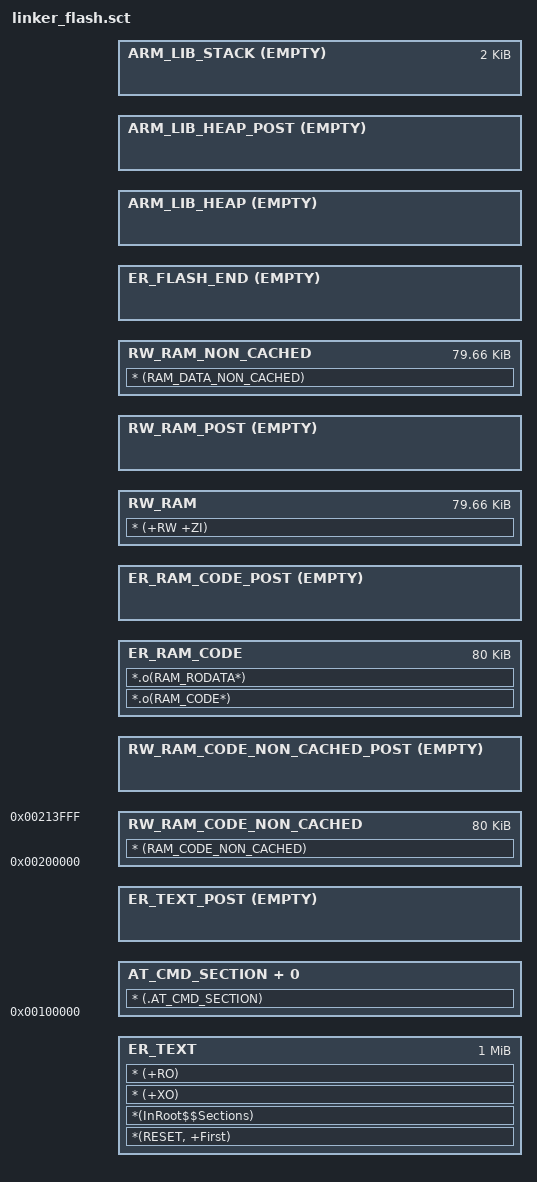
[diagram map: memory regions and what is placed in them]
#! armclang -E --target=arm-arm-none-eabi -mcpu=cortex-m4 -xc
; command above MUST be in first line (no comment above!)

/* ----------------------------------------------------------------------------
 * Copyright (c) 2020-2030 chipsea Limited. All rights reserved.
 *
 * Redistribution and use in source and binary forms, with or without modification,
 * are permitted provided that the following conditions are met:
 *   1. Redistributions of source code must retain the above copyright notice,
 *      this list of conditions and the following disclaimer.
 *   2. Redistributions in binary form must reproduce the above copyright notice,
 *      this list of conditions and the following disclaimer in the documentation
 *      and/or other materials provided with the distribution.
 *   3. Neither the name of chipseaelectronics nor the names of its contributors
 *      may be used to endorse or promote products derived from this software
 *      without specific prior written permission.
 *
 * THIS SOFTWARE IS PROVIDED BY THE COPYRIGHT HOLDERS AND CONTRIBUTORS "AS IS"
 * AND ANY EXPRESS OR IMPLIED WARRANTIES, INCLUDING, BUT NOT LIMITED TO, THE
 * IMPLIED WARRANTIES OF MERCHANTABILITY AND FITNESS FOR A PARTICULAR PURPOSE ARE
 * DISCLAIMED. IN NO EVENT SHALL THE COPYRIGHT HOLDER OR CONTRIBUTORS BE LIABLE
 * FOR ANY DIRECT, INDIRECT, INCIDENTAL, SPECIAL, EXEMPLARY, OR CONSEQUENTIAL
 * DAMAGES (INCLUDING, BUT NOT LIMITED TO, PROCUREMENT OF SUBSTITUTE GOODS OR
 * SERVICES; LOSS OF USE, DATA, OR PROFITS; OR BUSINESS INTERRUPTION) HOWEVER
 * CAUSED AND ON ANY THEORY OF LIABILITY, WHETHER IN CONTRACT, STRICT LIABILITY,
 * OR TORT (INCLUDING NEGLIGENCE OR OTHERWISE) ARISING IN ANY WAY OUT OF THE USE
 * OF THIS SOFTWARE, EVEN IF ADVISED OF THE POSSIBILITY OF SUCH DAMAGE.
 *
 * -------------------------------------------------------------------------- */

/**
 * @file     cst92f41_flash.sct
 * @brief    linker script for rom version
 * @date     19. Sept  2020
 * @author   chipsea
 *
 * @version
 * Version 1.0
 *  - Initial release
 *
 * @{
 */
 
/* #include "../../../../../../.autoconf.h" */

/*
;-------- <<< Use Configuration Wizard in Context Menu >>> -------------------
*/

/*--------------------- Flash Configuration ----------------------------------
; <h> Flash Configuration
;   <o0> Flash Base Address <0x0-0xFFFFFFFF:8>
;   <o1> Flash Size (in Bytes) <0x0-0xFFFFFFFF:8>
; </h>
 *----------------------------------------------------------------------------*/
#define __FLASH_BASE            0x00404000
#define __FLASH_SIZE            0x00100000

/*--------------------- Embedded RAM RO Configuration ---------------------------
; <h> RAM-RO Configuration
;   <o0> RAM RO Base Address    <0x0-0xFFFFFFFF:8>
;   <o1> RAM RO Size (in Bytes) <0x0-0xFFFFFFFF:8>
; </h>
 *----------------------------------------------------------------------------*/
#define __RAM_RO_BASE           0x00200000
#define __RAM_RO_SIZE           0x00014000

/*--------------------- Embedded RAM Configuration ---------------------------
; <h> RAM Configuration
;   <o0> RAM Base Address    <0x0-0xFFFFFFFF:8>
;   <o1> RAM Size (in Bytes) <0x0-0xFFFFFFFF:8>
; </h>
 *----------------------------------------------------------------------------*/
#define __RAM_BASE              0x20000000
#define __RAM_SIZE              0x00013ea0  /* The reduced SRAM is occupied by ROM */

/*--------------------- Stack / Heap Configuration ---------------------------
; <h> Stack / Heap Configuration
;   <o0> Stack Size (in Bytes) <0x0-0xFFFFFFFF:8>
;   <o1> General Heap Size (in Bytes) <0x0-0xFFFFFFFF:8>
; </h>
 *----------------------------------------------------------------------------*/
#define __STACK_SIZE            0x0800
#define __GENERAL_HEAP_SIZE     0x0000


/*
;------------- <<< end of configuration section >>> ---------------------------
*/


/*----------------------------------------------------------------------------
  Scatter File Definitions definition
 *----------------------------------------------------------------------------*/
LR_FLASH AlignExpr(__FLASH_BASE, 128) __FLASH_SIZE  {            ; load region size_region
    ER_TEXT AlignExpr(__FLASH_BASE, 128) __FLASH_SIZE  {                            ; load address = execution address
        *(RESET, +First)
        *(InRoot$$Sections)
        * (+XO)
        * (+RO)
    }

    ; AT command code
    AT_CMD_SECTION + 0 __FLASH_SIZE
    {
        * (.AT_CMD_SECTION)
    }

    ER_TEXT_POST +0 ALIGN 32 EMPTY 0 {    ; Reserve 0 bytes region for ER_TEXT
    }

    RW_RAM_CODE_NON_CACHED __RAM_RO_BASE ALIGN 32 __RAM_RO_SIZE {
        * (RAM_CODE_NON_CACHED)
    }
    RW_RAM_CODE_NON_CACHED_POST +0 ALIGN 32 EMPTY 0 {
    }

    ER_RAM_CODE +0 ALIGN 32 __RAM_RO_SIZE {
        *.o(RAM_CODE*)
        *.o(RAM_RODATA*)
    }
    ER_RAM_CODE_POST +0 ALIGN 32 EMPTY 0 {    ; Reserve 0 bytes region for ER_SRAM_CODE
    }

    RW_RAM __RAM_BASE + ImageLimit(ER_RAM_CODE_POST) - ImageBase(RW_RAM_CODE_NON_CACHED) ALIGN 32  __RAM_SIZE {                     ; RW data
        * (+RW +ZI)
    }
    RW_RAM_POST +0 ALIGN 32 EMPTY 0 {     ; Reserved 0 bytes region for RW_RAM
    }

    RW_RAM_NON_CACHED +0 ALIGN 32 __RAM_SIZE {
        * (RAM_DATA_NON_CACHED)
    }

    ER_FLASH_END +0 ALIGN 4 EMPTY 0 {  ; Reserve 0 bytes region for ER_FLASH_END
    }

    ARM_LIB_HEAP  +0 ALIGN 32 EMPTY __GENERAL_HEAP_SIZE  {   ; Reserve empty region for general heap
    }
    ARM_LIB_HEAP_POST +0 ALIGN 32 EMPTY 0 {   ; Reserve 0 bytes region for general heap
    }

    ARM_LIB_STACK +0 ALIGN 8 EMPTY __STACK_SIZE {   ; Reserve empty region for stack
    }

    ScatterAssert(LoadLength(LR_FLASH) < __FLASH_SIZE)
    ScatterAssert(ImageLimit(ARM_LIB_STACK) < (__RAM_BASE+__RAM_SIZE))
}

